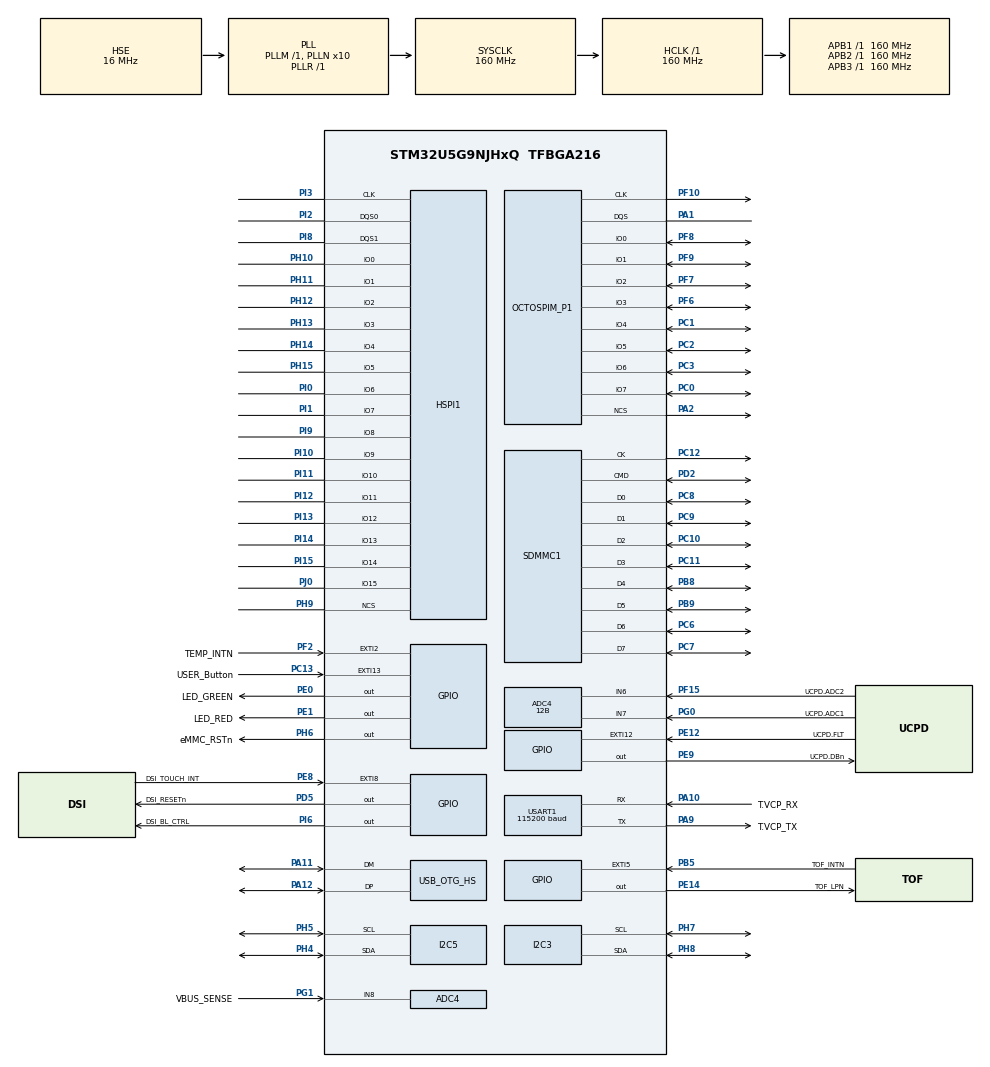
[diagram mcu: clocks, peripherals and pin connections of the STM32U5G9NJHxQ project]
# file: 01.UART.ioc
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ADC4.Channel-0\#ChannelRegularConversion=ADC_CHANNEL_6
ADC4.Channel-IN6=ADC_CHANNEL_6
ADC4.Channel-IN7=ADC_CHANNEL_7
ADC4.Channel-IN8=ADC_CHANNEL_8
ADC4.ClockPrescaler=ADC_CLOCK_ASYNC_DIV1
ADC4.ContinuousConvMode=DISABLE
ADC4.DMAContinuousRequests=DISABLE
ADC4.DataAlign=ADC_DATAALIGN_RIGHT
ADC4.DiscontinuousConvMode=DISABLE
ADC4.EOCSelection=ADC_EOC_SINGLE_CONV
ADC4.EnableAnalogWatchDog1=false
ADC4.EnableAnalogWatchDog2=false
ADC4.EnableAnalogWatchDog3=false
ADC4.EnableRegularConversion=ENABLE
ADC4.ExternalTrigConv=ADC_SOFTWARE_START
ADC4.ExternalTrigConvEdge=ADC_EXTERNALTRIGCONVEDGE_NONE
ADC4.LowPowerAutoPowerOff=ADC_LOW_POWER_NONE
ADC4.LowPowerAutoWait=DISABLE
ADC4.Mode=ADC_MODE_INDEPENDENT
ADC4.NbrOfConversion=1
ADC4.OffsetNumber-0\#ChannelRegularConversion=ADC_OFFSET_NONE
ADC4.Overrun=ADC_OVR_DATA_PRESERVED
ADC4.OversamplingMode=DISABLE
ADC4.Rank-0\#ChannelRegularConversion=1
ADC4.Resolution=ADC_RESOLUTION_12B
ADC4.SamplingTime-0\#ChannelRegularConversion=ADC4_SAMPLINGTIME_COMMON_1
ADC4.SamplingTimeCommon1=ADC4_SAMPLETIME_1CYCLE_5
ADC4.SamplingTimeCommon2=ADC4_SAMPLETIME_1CYCLE_5
ADC4.ScanConvMode=ADC4_SCAN_DISABLE
ADC4.SelectedChannel=ADC_CHANNEL_6|ADC_CHANNEL_7|ADC_CHANNEL_8
ADC4.Sequencer=FULLY_CONFIGURABLE
ADC4.TriggerFrequencyMode=ADC_TRIGGER_FREQ_LOW
CORTEX_M33_NS.MPU_Control=__NULL
CORTEX_M33_NS.userName=CORTEX_M33
DSI_CKN.Mode=DSIHost_Standalone
DSI_CKN.Signal=DSIHOST_CKN
DSI_CKP.Mode=DSIHost_Standalone
DSI_CKP.Signal=DSIHOST_CKP
DSI_D0N.Mode=DSIHost_Standalone
DSI_D0N.Signal=DSIHOST_D0N
DSI_D0P.Mode=DSIHost_Standalone
DSI_D0P.Signal=DSIHOST_D0P
DSI_D1N.Mode=DSIHost_Standalone
DSI_D1N.Signal=DSIHOST_D1N
DSI_D1P.Mode=DSIHost_Standalone
DSI_D1P.Signal=DSIHOST_D1P
HSPI1.ChipSelectBoundary=HAL_XSPI_BONDARYOF_NONE
HSPI1.ChipSelectHighTimeCycle=1
HSPI1.ClockMode=HAL_XSPI_CLOCK_MODE_0
HSPI1.ClockPrescaler=0
HSPI1.DelayHoldQuarterCycle=HAL_XSPI_DHQC_DISABLE
HSPI1.FifoThresholdByte=1
HSPI1.FreeRunningClock=HAL_XSPI_FREERUNCLK_DISABLE
HSPI1.MemoryMode=HAL_XSPI_SINGLE_MEM
HSPI1.MemorySize=HAL_XSPI_SIZE_16B
HSPI1.MemoryType=HAL_XSPI_MEMTYPE_MICRON
HSPI1.Refresh=0
HSPI1.SampleShifting=HAL_XSPI_SAMPLE_SHIFT_NONE
HSPI1.WrapSize=HAL_XSPI_WRAP_NOT_SUPPORTED
I2C3.AddressingMode=I2C_ADDRESSINGMODE_7BIT
I2C3.Analog_Filter=I2C_ANALOGFILTER_ENABLE
I2C3.AutonomousMode=AUTONOMOUS_MODE_DISABLE
I2C3.DualAddressMode=I2C_DUALADDRESS_DISABLE
I2C3.GeneralCallMode=I2C_GENERALCALL_DISABLE
I2C3.I2C_Coeff_DF=0
I2C3.I2C_Fall_Time=0
I2C3.I2C_Rise_Time=0
I2C3.NoStretchMode=I2C_NOSTRETCH_DISABLE
I2C3.OwnAddress=0
I2C3.Speed=100
I2C3.Timing=0x30909DEC
I2C5.AddressingMode=I2C_ADDRESSINGMODE_7BIT
I2C5.Analog_Filter=I2C_ANALOGFILTER_ENABLE
I2C5.AutonomousMode=AUTONOMOUS_MODE_DISABLE
I2C5.DualAddressMode=I2C_DUALADDRESS_DISABLE
I2C5.GeneralCallMode=I2C_GENERALCALL_DISABLE
I2C5.I2C_Coeff_DF=0
I2C5.I2C_Fall_Time=0
I2C5.I2C_Rise_Time=0
I2C5.NoStretchMode=I2C_NOSTRETCH_DISABLE
I2C5.OwnAddress=0
I2C5.Speed=100
I2C5.Timing=0x30909DEC
Mcu.Family=STM32U5
Mcu.Name=STM32U5G9NJHxQ
Mcu.Package=TFBGA216
NVIC.PriorityGroup=NVIC_PRIORITYGROUP_4
NVIC.USART1_IRQn=true\:0\:0\:false\:false\:true\:true\:true\:true
PA1.Mode=OCTOSPI1_Port1_DQS
PA1.Signal=OCTOSPIM_P1_DQS
PA10.GPIO_Label=T.VCP_RX
PA10.Mode=Asynchronous
PA10.Signal=USART1_RX
PA11.Mode=Internal_Phy_Device
PA11.Signal=USB_OTG_HS_DM
PA12.Mode=Internal_Phy_Device
PA12.Signal=USB_OTG_HS_DP
PA13\ (JTMS/SWDIO).Mode=Serial_Wire
PA13\ (JTMS/SWDIO).Signal=DEBUG_JTMS-SWDIO
PA14\ (JTCK/SWCLK).Mode=Serial_Wire
PA14\ (JTCK/SWCLK).Signal=DEBUG_JTCK-SWCLK
PA2.Mode=OCTOSPI1_Port1_NCS
PA2.Signal=OCTOSPIM_P1_NCS
PA9.GPIO_Label=T.VCP_TX
PA9.Mode=Asynchronous
PA9.Signal=USART1_TX
PB5.GPIO_Label=TOF_INTN
PB5.Signal=GPXTI5
PB8.Mode=mmc_8_bits_Wide_bus
PB8.Signal=SDMMC1_D4
PB9.Mode=mmc_8_bits_Wide_bus
PB9.Signal=SDMMC1_D5
PC0.Mode=OCTOSPI1_IOH_Port1H
PC0.Signal=OCTOSPIM_P1_IO7
PC1.Mode=OCTOSPI1_IOH_Port1H
PC1.Signal=OCTOSPIM_P1_IO4
PC10.Mode=mmc_8_bits_Wide_bus
PC10.Signal=SDMMC1_D2
PC11.Mode=mmc_8_bits_Wide_bus
PC11.Signal=SDMMC1_D3
PC12.Mode=mmc_8_bits_Wide_bus
PC12.Signal=SDMMC1_CK
PC13.GPIO_Label=USER_Button
PC13.Signal=GPXTI13
PC14-OSC32_IN\ (PC14).Mode=LSE-External-Oscillator
PC14-OSC32_IN\ (PC14).Signal=RCC_OSC32_IN
PC15-OSC32_OUT\ (PC15).Mode=LSE-External-Oscillator
PC15-OSC32_OUT\ (PC15).Signal=RCC_OSC32_OUT
PC2.Mode=OCTOSPI1_IOH_Port1H
PC2.Signal=OCTOSPIM_P1_IO5
PC3.Mode=OCTOSPI1_IOH_Port1H
PC3.Signal=OCTOSPIM_P1_IO6
PC6.Mode=mmc_8_bits_Wide_bus
PC6.Signal=SDMMC1_D6
PC7.Mode=mmc_8_bits_Wide_bus
PC7.Signal=SDMMC1_D7
PC8.Mode=mmc_8_bits_Wide_bus
PC8.Signal=SDMMC1_D0
PC9.Mode=mmc_8_bits_Wide_bus
PC9.Signal=SDMMC1_D1
PD2.Mode=mmc_8_bits_Wide_bus
PD2.Signal=SDMMC1_CMD
PD5.GPIO_Label=DSI_RESETn
PD5.Signal=GPIO_Output
PE0.GPIO_Label=LED_GREEN
PE0.Signal=GPIO_Output
PE1.GPIO_Label=LED_RED
PE1.Signal=GPIO_Output
PE12.GPIO_Label=UCPD.FLT
PE12.Signal=GPXTI12
PE14.GPIO_Label=TOF_LPN
PE14.Signal=GPIO_Output
PE8.GPIO_Label=DSI_TOUCH_INT
PE8.Signal=GPXTI8
PE9.GPIO_Label=UCPD.DBn
PE9.Signal=GPIO_Output
PF10.Mode=O1_P1_CLK
PF10.Signal=OCTOSPIM_P1_CLK
PF15.GPIO_Label=UCPD.ADC2
PF15.Mode=IN6
PF15.Signal=ADC4_IN6
PF2.GPIO_Label=TEMP_INTN
PF2.Signal=GPXTI2
PF6.Mode=OCTOSPI1_IOL_Port1L
PF6.Signal=OCTOSPIM_P1_IO3
PF7.Mode=OCTOSPI1_IOL_Port1L
PF7.Signal=OCTOSPIM_P1_IO2
PF8.Mode=OCTOSPI1_IOL_Port1L
PF8.Signal=OCTOSPIM_P1_IO0
PF9.Mode=OCTOSPI1_IOL_Port1L
PF9.Signal=OCTOSPIM_P1_IO1
PG0.GPIO_Label=UCPD.ADC1
PG0.Mode=IN7
PG0.Signal=ADC4_IN7
PG1.GPIO_Label=VBUS_SENSE
PG1.Mode=IN8
PG1.Signal=ADC4_IN8
PH0-OSC_IN\ (PH0).Mode=HSE-External-Oscillator
PH0-OSC_IN\ (PH0).Signal=RCC_OSC_IN
PH1-OSC_OUT\ (PH1).Mode=HSE-External-Oscillator
PH1-OSC_OUT\ (PH1).Signal=RCC_OSC_OUT
PH10.Mode=hexa_mode
PH10.Signal=HSPI1_IO0
PH11.Mode=hexa_mode
PH11.Signal=HSPI1_IO1
PH12.Mode=hexa_mode
PH12.Signal=HSPI1_IO2
PH13.Mode=hexa_mode
PH13.Signal=HSPI1_IO3
PH14.Mode=hexa_mode
PH14.Signal=HSPI1_IO4
PH15.Mode=hexa_mode
PH15.Signal=HSPI1_IO5
PH4.Mode=I2C
PH4.Signal=I2C5_SDA
PH5.Mode=I2C
PH5.Signal=I2C5_SCL
PH6.GPIO_Label=eMMC_RSTn
PH6.Signal=GPIO_Output
PH7.Mode=I2C
PH7.Signal=I2C3_SCL
PH8.Mode=I2C
PH8.Signal=I2C3_SDA
PH9.Mode=hexa_mode
PH9.Signal=HSPI1_NCS
PI0.Mode=hexa_mode
PI0.Signal=HSPI1_IO6
PI1.Mode=hexa_mode
PI1.Signal=HSPI1_IO7
PI10.Mode=hexa_mode
PI10.Signal=HSPI1_IO9
PI11.Mode=hexa_mode
PI11.Signal=HSPI1_IO10
PI12.Mode=hexa_mode
PI12.Signal=HSPI1_IO11
PI13.Mode=hexa_mode
PI13.Signal=HSPI1_IO12
PI14.Mode=hexa_mode
PI14.Signal=HSPI1_IO13
PI15.Mode=hexa_mode
PI15.Signal=HSPI1_IO14
PI2.Mode=hexa_mode
PI2.Signal=HSPI1_DQS0
PI3.Mode=hexa_mode
PI3.Signal=HSPI1_CLK
PI6.GPIO_Label=DSI_BL_CTRL
PI6.Signal=GPIO_Output
PI8.Mode=hexa_mode
PI8.Signal=HSPI1_DQS1
PI9.Mode=hexa_mode
PI9.Signal=HSPI1_IO8
PJ0.Mode=hexa_mode
PJ0.Signal=HSPI1_IO15
PWR.DMA2DPowerDownInStopMode=__NULL
PWR.DSIRAMPowerDownInStopMode=__NULL
PWR.Dcache1PowerDownInStopMode=__NULL
PWR.Dcache2PowerDownInStopMode=__NULL
PWR.GRAPHICPRAMPowerDownInStopMode=__NULL
PWR.IcachePowerDownInStopMode=__NULL
PWR.PeriphPowerDownInStopMode=__NULL
PWR.PowerMode=PWR_SMPS_SUPPLY
PWR.RAM1Page10PowerDownInStopMode=__NULL
PWR.RAM1Page11PowerDownInStopMode=__NULL
PWR.RAM1Page12PowerDownInStopMode=__NULL
PWR.RAM1Page1PowerDownInStopMode=__NULL
PWR.RAM1Page2PowerDownInStopMode=__NULL
PWR.RAM1Page3PowerDownInStopMode=__NULL
PWR.RAM1Page4PowerDownInStopMode=__NULL
PWR.RAM1Page5PowerDownInStopMode=__NULL
PWR.RAM1Page6PowerDownInStopMode=__NULL
PWR.RAM1Page7PowerDownInStopMode=__NULL
PWR.RAM1Page8PowerDownInStopMode=__NULL
PWR.RAM1Page9PowerDownInStopMode=__NULL
PWR.RAM2Page1PowerDownInStopMode=__NULL
PWR.RAM2Page2PowerDownInStopMode=__NULL
PWR.RAM3Page10PowerDownInStopMode=__NULL
PWR.RAM3Page11PowerDownInStopMode=__NULL
PWR.RAM3Page12PowerDownInStopMode=__NULL
PWR.RAM3Page13PowerDownInStopMode=__NULL
PWR.RAM3Page1PowerDownInStopMode=__NULL
PWR.RAM3Page2PowerDownInStopMode=__NULL
PWR.RAM3Page3PowerDownInStopMode=__NULL
PWR.RAM3Page4PowerDownInStopMode=__NULL
PWR.RAM3Page5PowerDownInStopMode=__NULL
PWR.RAM3Page6PowerDownInStopMode=__NULL
PWR.RAM3Page7PowerDownInStopMode=__NULL
PWR.RAM3Page8PowerDownInStopMode=__NULL
PWR.RAM3Page9PowerDownInStopMode=__NULL
PWR.RAM5Page10PowerDownInStopMode=__NULL
PWR.RAM5Page11PowerDownInStopMode=__NULL
PWR.RAM5Page12PowerDownInStopMode=__NULL
PWR.RAM5Page13PowerDownInStopMode=__NULL
PWR.RAM5Page1PowerDownInStopMode=__NULL
PWR.RAM5Page2PowerDownInStopMode=__NULL
PWR.RAM5Page3PowerDownInStopMode=__NULL
PWR.RAM5Page4PowerDownInStopMode=__NULL
PWR.RAM5Page5PowerDownInStopMode=__NULL
PWR.RAM5Page6PowerDownInStopMode=__NULL
PWR.RAM5Page7PowerDownInStopMode=__NULL
PWR.RAM5Page8PowerDownInStopMode=__NULL
PWR.RAM5Page9PowerDownInStopMode=__NULL
PWR.SRAM1PowerDownInRunMode=__NULL
PWR.SRAM2PowerDownInRunMode=__NULL
PWR.SRAM3PowerDownInRunMode=__NULL
PWR.SRAM4FastDownInRunMode=__NULL
PWR.SRAM4PowerDownInRunMode=__NULL
PWR.SRAM4PowerDownInStopMode=__NULL
PWR.SRAM5PowerDownInRunMode=__NULL
PWR.pwrPrivilege=PWR_PRIVILEGE_NO
ProjectManager.HeapSize=0x200
ProjectManager.StackSize=0x400
ProjectManager.TargetToolchain=STM32CubeIDE
RCC.ADCFreq_Value=16000000
RCC.AHBFreq_Value=160000000
RCC.APB1Freq_Value=160000000
RCC.APB1TimFreq_Value=160000000
RCC.APB2Freq_Value=160000000
RCC.APB2TimFreq_Value=160000000
RCC.APB3Freq_Value=160000000
RCC.CortexFreq_Value=160000000
RCC.EPOD_VALUE=16000000
RCC.HCLKFreq_Value=160000000
RCC.HSE_VALUE=16000000
RCC.HSI48_VALUE=48000000
RCC.HSI_VALUE=16000000
RCC.LSIDIV_VALUE=32000
RCC.MSIClockRange=RCC_MSIRANGE_0
RCC.MSI_VALUE=48000000
RCC.PLL1P=8
RCC.PLL1R=1
RCC.PLL2FRACN=0
RCC.PLL2M=4
RCC.PLL2N=36
RCC.PLL2R=24
RCC.PLL3FRACN=0
RCC.PLLFRACN=0
RCC.PLLN=10
RCC.SYSCLKFreq_VALUE=160000000
RCC.SYSCLKSource=RCC_SYSCLKSOURCE_PLLCLK
RCC.VCOOutputFreq_Value=160000000
SDMMC1.ClockDiv=0
SDMMC1.ClockEdge=SDMMC_CLOCK_EDGE_RISING
SDMMC1.ClockPowerSave=SDMMC_CLOCK_POWER_SAVE_DISABLE
SDMMC1.HardwareFlowControl=SDMMC_HARDWARE_FLOW_CONTROL_DISABLE
SDMMC1.TransceiverPresent=SDMMC_TRANSCEIVER_NOT_PRESENT
USART1.AutoBaudRateEnableParam=UART_ADVFEATURE_AUTOBAUDRATE_DISABLE
USART1.AutonomousMode=AUTONOMOUS_MODE_DISABLE
USART1.BaudRate=115200
USART1.ClockPrescaler=PRESCALER_DIV1
USART1.DMADisableonRxErrorParam=ADVFEATURE_DMA_ENABLEONRXERROR
USART1.DataInvertParam=ADVFEATURE_DATAINV_DISABLE
USART1.FIFOMode=FIFOMODE_DISABLE
USART1.MSBFirstParam=ADVFEATURE_MSBFIRST_DISABLE
USART1.Mode=MODE_TX_RX
USART1.OneBitSampling=UART_ONE_BIT_SAMPLE_DISABLE
USART1.OverSampling=UART_OVERSAMPLING_16
USART1.OverrunDisableParam=ADVFEATURE_OVERRUN_ENABLE
USART1.Parity=PARITY_NONE
USART1.RXFIFOThreshold=RXFIFO_THRESHOLD_1EIGHTHFULL
USART1.RxPinLevelInvertParam=ADVFEATURE_RXINV_DISABLE
USART1.StopBits=STOPBITS_1
USART1.SwapParam=ADVFEATURE_SWAP_DISABLE
USART1.TXFIFOThreshold=TXFIFO_THRESHOLD_1EIGHTHFULL
USART1.TxPinLevelInvertParam=ADVFEATURE_TXINV_DISABLE
USART1.VirtualMode-Asynchronous=VM_ASYNC
USART1.WordLength=WORDLENGTH_8B
USB_OTG_HS.VirtualMode=Device_HS
VP_ICACHE_VS_ICACHE.Mode=DirectMappedCache
VP_LPBAMQUEUE_VS_QUEUE.Mode=QUEUEMODE
VP_LPBAM_VS_SIG1.Mode=SmartRun
VP_LPBAM_VS_SIG4.Mode=LPDMA1
VP_LTDC_DSIMode.Mode=RGB888
VP_MEMORYMAP_VS_MEMORYMAP.Mode=CurAppReg
VP_OCTOSPI1_VS_octo.Mode=octo_mode
VP_PWR_VS_DBSignals.Mode=DisableDeadBatterySignals
VP_PWR_VS_LPOM.Mode=PowerOptimisation
VP_PWR_VS_SECSignals.Mode=Security/Privilege
VP_PWR_Vdda.Mode=isolationVdda
board=STM32U5G9J-DK1

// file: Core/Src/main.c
/* USER CODE BEGIN Header */
/**
  ******************************************************************************
  * @file           : main.c
  * @brief          : Main program body
  ******************************************************************************
  * @attention
  *
  * Copyright (c) 2024 STMicroelectronics.
  * All rights reserved.
  *
  * This software is licensed under terms that can be found in the LICENSE file
  * in the root directory of this software component.
  * If no LICENSE file comes with this software, it is provided AS-IS.
  *
  ******************************************************************************
  */
/* USER CODE END Header */
#include "main.h"
#include "adc.h"
#include "dsihost.h"
#include "hspi.h"
#include "i2c.h"
#include "icache.h"
#include "ltdc.h"
#include "memorymap.h"
#include "octospi.h"
#include "sdmmc.h"
#include "usart.h"
#include "usb_otg.h"
#include "gpio.h"

/* USER CODE BEGIN Includes */
#include "stdio.h"
#include "string.h"
/* USER CODE END Includes */

/* USER CODE BEGIN PV */
int count = 0;
/* USER CODE END PV */

void SystemClock_Config(void);
static void SystemPower_Config(void);

/* USER CODE BEGIN 0 */
//int _write(int file, char* pData ,int len )
//{
//	HAL_UART_Transmit(&huart1, (uint8_t*)pData, len, 10);  // VCP 확인용
////	for(uint32_t i=0; i<len; i++)
////	{
////		ITM_SendChar((*pData++));  // SWV 확인용
////	}
//	return len;
//}
/* USER CODE END 0 */

int main(void)
{

  /* MCU Configuration--------------------------------------------------------*/

  /* Reset of all peripherals, Initializes the Flash interface and the Systick. */
  HAL_Init();

  /* Configure the System Power */
  SystemPower_Config();

  /* Configure the system clock */
  SystemClock_Config();

  /* Initialize all configured peripherals */
  MX_GPIO_Init();
  MX_ADC4_Init();
  MX_HSPI1_Init();
  MX_I2C3_Init();
  MX_I2C5_Init();
  MX_ICACHE_Init();
  MX_OCTOSPI1_Init();
  MX_SDMMC1_MMC_Init();
  MX_USART1_UART_Init();
  MX_USB_OTG_HS_PCD_Init();
  MX_DSIHOST_DSI_Init();
  MX_LTDC_Init();

  /* Infinite loop */
  /* USER CODE BEGIN WHILE */
  while (1)
  {
	  count++;
	  HAL_GPIO_TogglePin(GPIOE, LED_GREEN_Pin);
	  //printf("[%d]\r\n", count++);
	  HAL_Delay(1000);
    /* USER CODE END WHILE */

  }
}

void SystemClock_Config(void)
{
  RCC_OscInitTypeDef RCC_OscInitStruct = {0};
  RCC_ClkInitTypeDef RCC_ClkInitStruct = {0};

  /** Configure the main internal regulator output voltage
  */
  if (HAL_PWREx_ControlVoltageScaling(PWR_REGULATOR_VOLTAGE_SCALE1) != HAL_OK)
  {
    Error_Handler();
  }

  /** Initializes the CPU, AHB and APB buses clocks
  */
  RCC_OscInitStruct.OscillatorType = RCC_OSCILLATORTYPE_HSI|RCC_OSCILLATORTYPE_HSE
                              |RCC_OSCILLATORTYPE_MSI;
  RCC_OscInitStruct.HSEState = RCC_HSE_ON;
  RCC_OscInitStruct.HSIState = RCC_HSI_ON;
  RCC_OscInitStruct.HSICalibrationValue = RCC_HSICALIBRATION_DEFAULT;
  RCC_OscInitStruct.MSIState = RCC_MSI_ON;
  RCC_OscInitStruct.MSICalibrationValue = RCC_MSICALIBRATION_DEFAULT;
  RCC_OscInitStruct.MSIClockRange = RCC_MSIRANGE_0;
  RCC_OscInitStruct.PLL.PLLState = RCC_PLL_ON;
  RCC_OscInitStruct.PLL.PLLSource = RCC_PLLSOURCE_HSE;
  RCC_OscInitStruct.PLL.PLLMBOOST = RCC_PLLMBOOST_DIV1;
  RCC_OscInitStruct.PLL.PLLM = 1;
  RCC_OscInitStruct.PLL.PLLN = 10;
  RCC_OscInitStruct.PLL.PLLP = 8;
  RCC_OscInitStruct.PLL.PLLQ = 2;
  RCC_OscInitStruct.PLL.PLLR = 1;
  RCC_OscInitStruct.PLL.PLLRGE = RCC_PLLVCIRANGE_1;
  RCC_OscInitStruct.PLL.PLLFRACN = 0;
  if (HAL_RCC_OscConfig(&RCC_OscInitStruct) != HAL_OK)
  {
    Error_Handler();
  }

  /** Initializes the CPU, AHB and APB buses clocks
  */
  RCC_ClkInitStruct.ClockType = RCC_CLOCKTYPE_HCLK|RCC_CLOCKTYPE_SYSCLK
                              |RCC_CLOCKTYPE_PCLK1|RCC_CLOCKTYPE_PCLK2
                              |RCC_CLOCKTYPE_PCLK3;
  RCC_ClkInitStruct.SYSCLKSource = RCC_SYSCLKSOURCE_PLLCLK;
  RCC_ClkInitStruct.AHBCLKDivider = RCC_SYSCLK_DIV1;
  RCC_ClkInitStruct.APB1CLKDivider = RCC_HCLK_DIV1;
  RCC_ClkInitStruct.APB2CLKDivider = RCC_HCLK_DIV1;
  RCC_ClkInitStruct.APB3CLKDivider = RCC_HCLK_DIV1;

  if (HAL_RCC_ClockConfig(&RCC_ClkInitStruct, FLASH_LATENCY_4) != HAL_OK)
  {
    Error_Handler();
  }
}

/**
  * @brief Power Configuration
  * @retval None
  */
static void SystemPower_Config(void)
{

  /*
   * Disable the internal Pull-Up in Dead Battery pins of UCPD peripheral
   */
  HAL_PWREx_DisableUCPDDeadBattery();

  /*
   * Switch to SMPS regulator instead of LDO
   */
  if (HAL_PWREx_ConfigSupply(PWR_SMPS_SUPPLY) != HAL_OK)
  {
    Error_Handler();
  }
}

void Error_Handler(void)
{
  __disable_irq();
  while (1)
  {
  }
}
